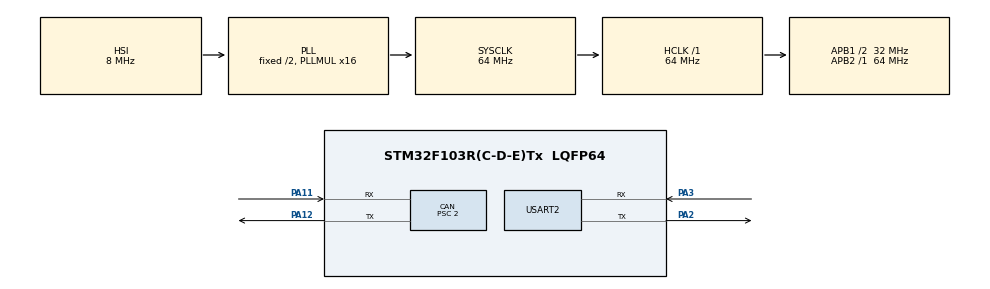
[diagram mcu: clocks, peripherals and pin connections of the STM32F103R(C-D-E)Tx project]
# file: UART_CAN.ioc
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Mcu.Family=STM32F1
FREERTOS.Queues01=Queue_CAN,8,uint8_t,0,Dynamic,NULL,NULL;Queue_UART,8,uint8_t,0,Dynamic,NULL,NULL
NVIC.CAN1_RX1_IRQn=true\:5\:0\:false\:false\:true\:true\:true\:true
FREERTOS.Tasks01=defaultTask,8,128,StartDefaultTask,Default,NULL,Dynamic,NULL,NULL;Task_UART2CAN,24,128,StartTask_UART2CAN,Default,NULL,Dynamic,NULL,NULL;Task_CAN2UART,24,128,StartTask_CAN2UART,Default,NULL,Dynamic,NULL,NULL
PD1-OSC_OUT.Mode=HSE-External-Oscillator
CAN.CalculateBaudRate=1000000
VP_SYS_VS_tim7.Mode=TIM7
PA11.Mode=CAN_Activate
PD0-OSC_IN.Signal=RCC_OSC_IN
RCC.APB1CLKDivider=RCC_HCLK_DIV2
NVIC.USART2_IRQn=true\:5\:0\:false\:false\:true\:true\:true\:true
CAN.CalculateTimeBit=1000.00
RCC.SYSCLKSource=RCC_SYSCLKSOURCE_PLLCLK
ProjectManager.StackSize=0x400
VP_FREERTOS_VS_CMSIS_V2.Mode=CMSIS_V2
PD1-OSC_OUT.Signal=RCC_OSC_OUT
PA13.Signal=SYS_JTMS-SWDIO
PA3.Mode=Asynchronous
CAN.BS2=CAN_BS2_2TQ
PA12.Signal=CAN_TX
CAN.BS1=CAN_BS1_13TQ
CAN.Prescaler=2
ProjectManager.TargetToolchain=Makefile
RCC.HCLKFreq_Value=64000000
RCC.APB2TimFreq_Value=64000000
RCC.USBFreq_Value=64000000
NVIC.CAN1_SCE_IRQn=true\:5\:0\:false\:false\:true\:true\:true\:true
RCC.AHBFreq_Value=64000000
PD0-OSC_IN.Mode=HSE-External-Oscillator
RCC.HSE_VALUE=16000000
board=custom
RCC.PLLMUL=RCC_PLL_MUL16
RCC.APB2Freq_Value=64000000
PA14.Mode=Serial_Wire
CAN.NART=ENABLE
PA13.Mode=Serial_Wire
Mcu.Name=STM32F103R(C-D-E)Tx
CAN.CalculateTimeQuantum=62.5
PA2.Signal=USART2_TX
RCC.SYSCLKFreq_VALUE=64000000
Mcu.Package=LQFP64
NVIC.TimeBase=TIM7_IRQn
PA12.Mode=CAN_Activate
USART2.VirtualMode=VM_ASYNC
PA11.Signal=CAN_RX
NVIC.TimeBaseIP=TIM7
PA14.Signal=SYS_JTCK-SWCLK
ProjectManager.HeapSize=0x200
NVIC.PriorityGroup=NVIC_PRIORITYGROUP_4
RCC.APB1TimFreq_Value=64000000
PA2.Mode=Asynchronous
RCC.APB1Freq_Value=32000000
NVIC.TIM7_IRQn=true\:0\:0\:false\:false\:true\:false\:false\:true
PA3.Signal=USART2_RX

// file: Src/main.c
/* USER CODE BEGIN Header */
/**
  ******************************************************************************
  * @file           : main.c
  * @brief          : Main program body
  ******************************************************************************
  * @attention
  *
  * <h2><center>&copy; Copyright (c) 2021 STMicroelectronics.
  * All rights reserved.</center></h2>
  *
  * This software component is licensed by ST under Ultimate Liberty license
  * SLA0044, the "License"; You may not use this file except in compliance with
  * the License. You may obtain a copy of the License at:
  *                             www.st.com/SLA0044
  *
  ******************************************************************************
  */
/* USER CODE END Header */
#include "main.h"
// #include "cmsis_os.h"
#include "can.h"
#include "usart.h"
#include "gpio.h"

/* USER CODE BEGIN Includes */
#include <string.h>
#include "cmsis_os2.h"
/* USER CODE END Includes */

void SystemClock_Config(void);
void MX_FREERTOS_Init(void);

int main(void)
{

  /* MCU Configuration--------------------------------------------------------*/

  /* Reset of all peripherals, Initializes the Flash interface and the Systick. */
  HAL_Init();

  /* Configure the system clock */
  SystemClock_Config();

  /* Initialize all configured peripherals */
  MX_GPIO_Init();
  MX_CAN_Init();
  MX_USART2_UART_Init();

  /* Init scheduler */
  osKernelInitialize();  /* Call init function for freertos objects (in freertos.c) */
  MX_FREERTOS_Init();
  /* Start scheduler */
  osKernelStart();

  /* We should never get here as control is now taken by the scheduler */
  /* Infinite loop */
  while (1)
  {

  }
}

void SystemClock_Config(void)
{
  RCC_OscInitTypeDef RCC_OscInitStruct = {0};
  RCC_ClkInitTypeDef RCC_ClkInitStruct = {0};

  /** Initializes the RCC Oscillators according to the specified parameters
  * in the RCC_OscInitTypeDef structure.
  */
  RCC_OscInitStruct.OscillatorType = RCC_OSCILLATORTYPE_HSI;
  RCC_OscInitStruct.HSIState = RCC_HSI_ON;
  RCC_OscInitStruct.HSICalibrationValue = RCC_HSICALIBRATION_DEFAULT;
  RCC_OscInitStruct.PLL.PLLState = RCC_PLL_ON;
  RCC_OscInitStruct.PLL.PLLSource = RCC_PLLSOURCE_HSI_DIV2;
  RCC_OscInitStruct.PLL.PLLMUL = RCC_PLL_MUL16;
  if (HAL_RCC_OscConfig(&RCC_OscInitStruct) != HAL_OK)
  {
    Error_Handler();
  }
  /** Initializes the CPU, AHB and APB buses clocks
  */
  RCC_ClkInitStruct.ClockType = RCC_CLOCKTYPE_HCLK|RCC_CLOCKTYPE_SYSCLK
                              |RCC_CLOCKTYPE_PCLK1|RCC_CLOCKTYPE_PCLK2;
  RCC_ClkInitStruct.SYSCLKSource = RCC_SYSCLKSOURCE_PLLCLK;
  RCC_ClkInitStruct.AHBCLKDivider = RCC_SYSCLK_DIV1;
  RCC_ClkInitStruct.APB1CLKDivider = RCC_HCLK_DIV2;
  RCC_ClkInitStruct.APB2CLKDivider = RCC_HCLK_DIV1;

  if (HAL_RCC_ClockConfig(&RCC_ClkInitStruct, FLASH_LATENCY_2) != HAL_OK)
  {
    Error_Handler();
  }
}

 /**
  * @brief  Period elapsed callback in non blocking mode
  * @note   This function is called  when TIM7 interrupt took place, inside
  * HAL_TIM_IRQHandler(). It makes a direct call to HAL_IncTick() to increment
  * a global variable "uwTick" used as application time base.
  * @param  htim : TIM handle
  * @retval None
  */
void HAL_TIM_PeriodElapsedCallback(TIM_HandleTypeDef *htim)
{
  if (htim->Instance == TIM7) {
    HAL_IncTick();
  }
}

void Error_Handler(void)
{
  __disable_irq();
  while (1)
  {
  }
}

/************************ (C) COPYRIGHT STMicroelectronics *****END OF FILE****/

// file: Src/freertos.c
/* USER CODE BEGIN Header */
/**
  ******************************************************************************
  * File Name          : freertos.c
  * Description        : Code for freertos applications
  ******************************************************************************
  * @attention
  *
  * <h2><center>&copy; Copyright (c) 2021 STMicroelectronics.
  * All rights reserved.</center></h2>
  *
  * This software component is licensed by ST under Ultimate Liberty license
  * SLA0044, the "License"; You may not use this file except in compliance with
  * the License. You may obtain a copy of the License at:
  *                             www.st.com/SLA0044
  *
  ******************************************************************************
  */
/* USER CODE END Header */

#include "FreeRTOS.h"
#include "task.h"
#include "main.h"
// #include "cmsis_os.h"

/* USER CODE BEGIN Includes */
#include <string.h>
#include "cmsis_os2.h"
#include "slip_exchange.h"
/* USER CODE END Includes */

/* Definitions for defaultTask */
osThreadId_t defaultTaskHandle;
const osThreadAttr_t defaultTask_attributes = {
  .name = "defaultTask",
  .priority = (osPriority_t) osPriorityLow,
  .stack_size = 128 * 4
};
/* Definitions for Task_UART2CAN */
osThreadId_t Task_UART2CANHandle;
const osThreadAttr_t Task_UART2CAN_attributes = {
  .name = "Task_UART2CAN",
  .priority = (osPriority_t) osPriorityNormal,
  .stack_size = 128 * 4
};
/* Definitions for Task_CAN2UART */
osThreadId_t Task_CAN2UARTHandle;
const osThreadAttr_t Task_CAN2UART_attributes = {
  .name = "Task_CAN2UART",
  .priority = (osPriority_t) osPriorityNormal,
  .stack_size = 128 * 4
};
/* Definitions for Queue_CAN */
osMessageQueueId_t Queue_CANHandle;
const osMessageQueueAttr_t Queue_CAN_attributes = {
  .name = "Queue_CAN"
};
/* Definitions for Queue_UART */
osMessageQueueId_t Queue_UARTHandle;
const osMessageQueueAttr_t Queue_UART_attributes = {
  .name = "Queue_UART"
};

void StartDefaultTask(void *argument);
void StartTask_UART2CAN(void *argument);
void StartTask_CAN2UART(void *argument);

void MX_FREERTOS_Init(void); /* (MISRA C 2004 rule 8.1) */

void MX_FREERTOS_Init(void) {

  /* Create the queue(s) */
  /* creation of Queue_CAN */
  Queue_CANHandle = osMessageQueueNew (8, sizeof(uint8_t), &Queue_CAN_attributes);

  /* creation of Queue_UART */
  Queue_UARTHandle = osMessageQueueNew (8, sizeof(uint8_t), &Queue_UART_attributes);

  /* Create the thread(s) */
  /* creation of defaultTask */
  defaultTaskHandle = osThreadNew(StartDefaultTask, NULL, &defaultTask_attributes);

  /* creation of Task_UART2CAN */
  Task_UART2CANHandle = osThreadNew(StartTask_UART2CAN, NULL, &Task_UART2CAN_attributes);

  /* creation of Task_CAN2UART */
  Task_CAN2UARTHandle = osThreadNew(StartTask_CAN2UART, NULL, &Task_CAN2UART_attributes);

}

void StartDefaultTask(void *argument)
{
  for(;;)
  {
    osDelay(1);
  }
}

void StartTask_UART2CAN(void *argument)
{
  /* USER CODE BEGIN StartTask_UART2CAN */
  slip_decode_t slip_decode;
  uint8_t queue_rec[10] = {0};
  /* Infinite loop */
  for(;;)
  {
    osDelay(1);
    if(osMessageQueueGet(Queue_UARTHandle, queue_rec, NULL, osWaitForever) == osOK)
    {
      memcpy(&slip_decode.uart_array, queue_rec, 10);
      if(uart_to_can(&slip_decode) == -1)
      {
        //TODO
      }
    }
  }
  /* USER CODE END StartTask_UART2CAN */
}

void StartTask_CAN2UART(void *argument)
{
  for(;;)
  {
    osDelay(1);
  }
}

/************************ (C) COPYRIGHT STMicroelectronics *****END OF FILE****/
